# ESP32-P4 register map
Vendor: ESPRESSIF SYSTEMS (SHANGHAI) CO., LTD.; Series: ESP32 P-Series; File version: 2
CPU: RV32IMAFC r0p0, little endian, no MPU, FPU, 0 interrupt priority bits
Address unit: 32 bits
Registers are 32-bit, read-write, reset 0x0 unless marked. A register's access mark holds for its fields unless they carry their own. Offsets are from the block's base; [hi:lo] are bit positions; {n}, {i} and the like mark numbered series.

## AES — AES (Advanced Encryption Standard) Accelerator
Base 0x50090000
{0x0+4i} KEY_{i} (i=0..7) — Key material key_{i} configure register
  [31:0] KEY_{i} — This bits stores key_{i} that is a part of key material.
{0x20+4i} TEXT_IN_{i} (i=0..3) — source text material text_in_{i} configure register
  [31:0] TEXT_IN_{i} — This bits stores text_in_{i} that is a part of source text material.
{0x30+4i} TEXT_OUT_{i} (i=0..3) — result text material text_out_{i} configure register
  [31:0] TEXT_OUT_{i} — This bits stores text_out_{i} that is a part of result text material.
0x40 MODE — AES Mode register
  [2:0] MODE — This bits decides which one operation mode will be used. 3'd0: AES-EN-128, 3'd1: AES-EN-192, 3'd2: AES-EN-256, 3'd4: AES-DE-128, 3'd5: AES-DE-192, 3'd6: AES-DE-256.
0x44 ENDIAN — AES Endian configure register
  [5:0] ENDIAN — endian. [1:0] key endian, [3:2] text_in endian or in_stream endian, [5:4] text_out endian or out_stream endian
0x48 TRIGGER wo — AES trigger register
  [0] TRIGGER — Set this bit to start AES calculation.
0x4C STATE ro — AES state register
  [1:0] STATE — Those bits shows AES status. For typical AES, 0: idle, 1: busy. For DMA-AES, 0: idle, 1: busy, 2: calculation_done.
{0x50+4i} IV_MEM[{i}] (i=0..3) access not given — The memory that stores initialization vector
{0x60+4i} H_MEM[{i}] (i=0..3) access not given — The memory that stores GCM hash subkey
{0x70+4i} J0_MEM[{i}] (i=0..3) access not given — The memory that stores J0
{0x80+4i} T0_MEM[{i}] (i=0..3) access not given — The memory that stores T0
0x90 DMA_ENABLE — DMA-AES working mode register
  [0] DMA_ENABLE — 1'b0: typical AES working mode, 1'b1: DMA-AES working mode.
0x94 BLOCK_MODE — AES cipher block mode register
  [2:0] BLOCK_MODE — Those bits decides which block mode will be used. 0x0: ECB, 0x1: CBC, 0x2: OFB, 0x3: CTR, 0x4: CFB-8, 0x5: CFB-128, 0x6: GCM, 0x7: reserved.
0x98 BLOCK_NUM — AES block number register
  [31:0] BLOCK_NUM — Those bits stores the number of Plaintext/ciphertext block.
0x9C INC_SEL — Standard incrementing function configure register
  [0] INC_SEL — This bit decides the standard incrementing function. 0: INC32. 1: INC128.
0xA0 AAD_BLOCK_NUM — Additional Authential Data block number register
  [31:0] AAD_BLOCK_NUM — Those bits stores the number of AAD block.
0xA4 REMAINDER_BIT_NUM — AES remainder bit number register
  [6:0] REMAINDER_BIT_NUM — Those bits stores the number of remainder bit.
0xA8 CONTINUE wo — AES continue register
  [0] CONTINUE — Set this bit to continue GCM operation.
0xAC INT_CLEAR wo — AES Interrupt clear register
  [0] INT_CLEAR — Set this bit to clear the AES interrupt.
0xB0 INT_ENA — AES Interrupt enable register
  [0] INT_ENA — Set this bit to enable interrupt that occurs when DMA-AES calculation is done.
0xB4 DATE reset 0x20191210 — AES version control register
  [29:0] DATE — This bits stores the version information of AES.
0xB8 DMA_EXIT wo — AES-DMA exit config
  [0] DMA_EXIT — Set this register to leave calculation done stage. Recommend to use it after software finishes reading DMA's output buffer.

## LP_I2C_ANA_MST — LP_I2C_ANA_MST Peripheral
Base 0x50124000
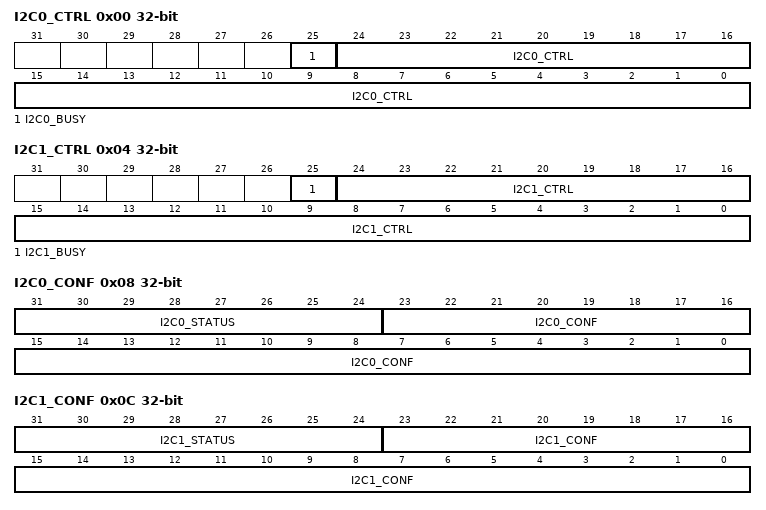
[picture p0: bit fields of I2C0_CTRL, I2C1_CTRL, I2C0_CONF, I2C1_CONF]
0x00 I2C0_CTRL access per field — need des
  [25] I2C0_BUSY ro — need des
  [24:0] I2C0_CTRL rw — need des
0x04 I2C1_CTRL access per field — need des
  [25] I2C1_BUSY ro — need des
  [24:0] I2C1_CTRL rw — need des
0x08 I2C0_CONF access per field — need des
  [31:24] I2C0_STATUS ro — need des
  [23:0] I2C0_CONF rw — need des
0x0C I2C1_CONF access per field — need des
  [31:24] I2C1_STATUS ro — need des
  [23:0] I2C1_CONF rw — need des
0x10 I2C_BURST_CONF — need des
  [31:0] I2C_MST_BURST_CTRL
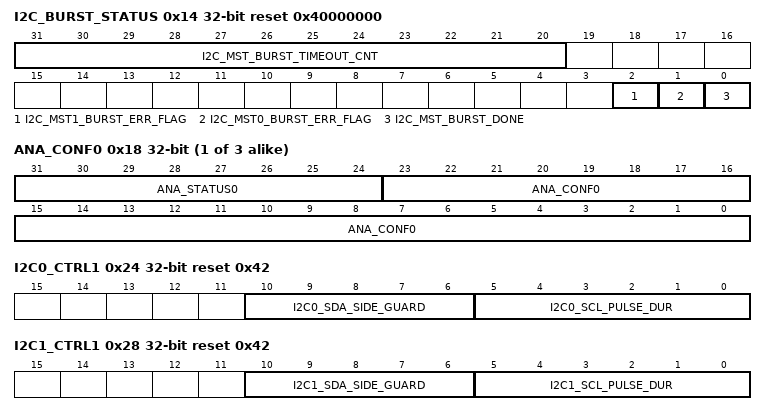
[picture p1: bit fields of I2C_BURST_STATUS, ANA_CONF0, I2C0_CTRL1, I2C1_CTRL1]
0x14 I2C_BURST_STATUS access per field reset 0x40000000 — need des
  [31:20] I2C_MST_BURST_TIMEOUT_CNT rw — need des
  [2] I2C_MST1_BURST_ERR_FLAG ro — need des
  [1] I2C_MST0_BURST_ERR_FLAG ro — need des
  [0] I2C_MST_BURST_DONE ro — need des
{0x18+4i} ANA_CONF{i} access per field (i=0..2) — need des
  [31:24] ANA_STATUS{i} ro — need des
  [23:0] ANA_CONF{i} rw — need des
0x24 I2C0_CTRL1 reset 0x42 — need des
  [10:6] I2C0_SDA_SIDE_GUARD — need des
  [5:0] I2C0_SCL_PULSE_DUR — need des
0x28 I2C1_CTRL1 reset 0x42 — need des
  [10:6] I2C1_SDA_SIDE_GUARD — need des
  [5:0] I2C1_SCL_PULSE_DUR — need des
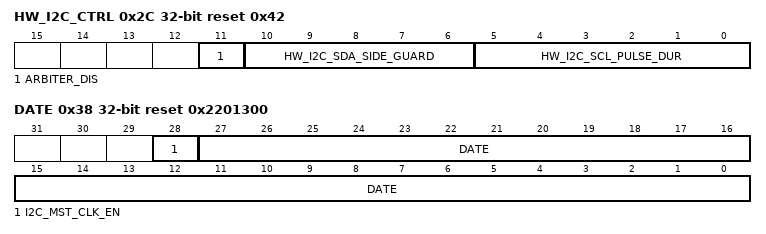
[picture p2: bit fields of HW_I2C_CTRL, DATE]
0x2C HW_I2C_CTRL reset 0x42 — need des
  [11] ARBITER_DIS — need des
  [10:6] HW_I2C_SDA_SIDE_GUARD — need des
  [5:0] HW_I2C_SCL_PULSE_DUR — need des
0x30 NOUSE — need des
  [31:0] I2C_MST_NOUSE
0x34 CLK160M — need des
  [0] CLK_I2C_MST_SEL_160M
0x38 DATE reset 0x2201300 — need des
  [28] I2C_MST_CLK_EN — need des
  [27:0] DATE — need des
